# STM32F302x register map
File version: 1.1
Registers are 32-bit, read-write, reset 0x0 unless marked. A register's access mark holds for its fields unless they carry their own. Offsets are from the block's base; [hi:lo] are bit positions; {n}, {i} and the like mark numbered series.

## EXTI — External interrupt/event controller
Base 0x40010400
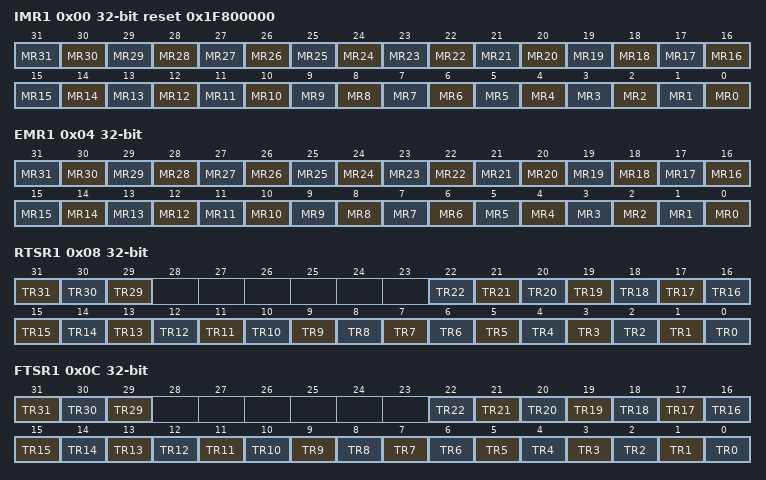
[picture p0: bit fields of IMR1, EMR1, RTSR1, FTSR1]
0x00 IMR1 reset 0x1F800000 — Interrupt mask register
  [n] MR{n} (n=0..31) — Interrupt Mask on line {n}
0x04 EMR1 — Event mask register
  [n] MR{n} (n=0..31) — Event Mask on line {n}
0x08 RTSR1 — Rising Trigger selection register
  [31] TR31 — Rising trigger event configuration of line 31
  [30] TR30 — Rising trigger event configuration of line 30
  [29] TR29 — Rising trigger event configuration of line 29
  [n] TR{n} (n=0..22) — Rising trigger event configuration of line {n}
0x0C FTSR1 — Falling Trigger selection register
  [31] TR31 — Falling trigger event configuration of line 31
  [30] TR30 — Falling trigger event configuration of line 30.
  [29] TR29 — Falling trigger event configuration of line 29
  [n] TR{n} (n=0..22) — Falling trigger event configuration of line {n}
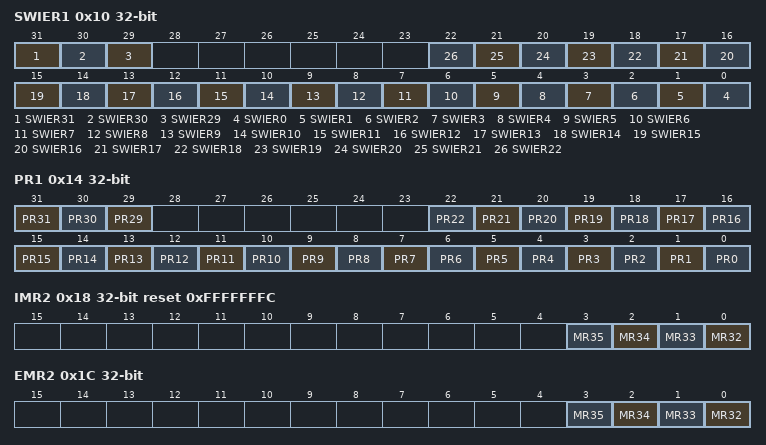
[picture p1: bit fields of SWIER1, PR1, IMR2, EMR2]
0x10 SWIER1 — Software interrupt event register
  [31] SWIER31 — Software Interrupt on line 319
  [30] SWIER30 — Software Interrupt on line 309
  [29] SWIER29 — Software Interrupt on line 29
  [n] SWIER{n} (n=0..22) — Software Interrupt on line {n}
0x14 PR1 — Pending register
  [31] PR31 — Pending bit 31
  [30] PR30 — Pending bit 30
  [29] PR29 — Pending bit 29
  [n] PR{n} (n=0..22) — Pending bit {n}
0x18 IMR2 reset 0xFFFFFFFC — Interrupt mask register
  [n-32] MR{n} (n=32..35) — Interrupt Mask on external/internal line {n}
0x1C EMR2 — Event mask register
  [n-32] MR{n} (n=32..35) — Event mask on external/internal line {n}
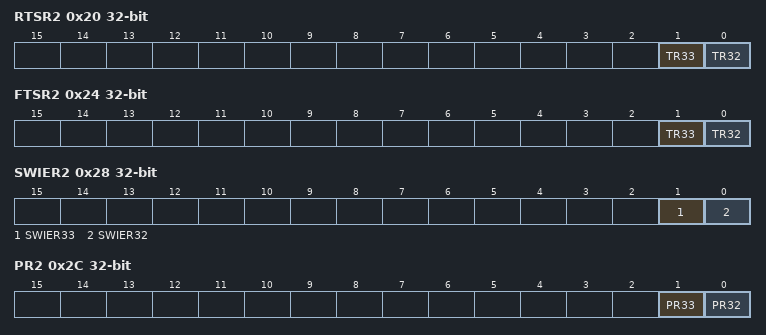
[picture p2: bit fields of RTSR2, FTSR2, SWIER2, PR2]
0x20 RTSR2 — Rising Trigger selection register
  [1] TR33 — Rising trigger event configuration bit of line 33
  [0] TR32 — Rising trigger event configuration bit of line 32
0x24 FTSR2 — Falling Trigger selection register
  [1] TR33 — Falling trigger event configuration bit of line 33
  [0] TR32 — Falling trigger event configuration bit of line 32
0x28 SWIER2 — Software interrupt event register
  [1] SWIER33 — Software interrupt on line 33
  [0] SWIER32 — Software interrupt on line 32
0x2C PR2 — Pending register
  [1] PR33 — Pending bit on line 33
  [0] PR32 — Pending bit on line 32

## COMP — Comparator
Base 0x4001001C
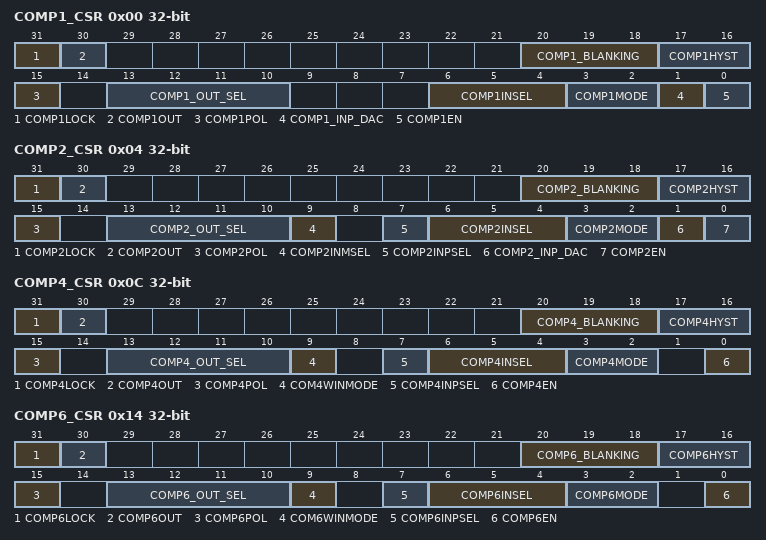
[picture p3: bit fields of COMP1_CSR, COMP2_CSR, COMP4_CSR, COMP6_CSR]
0x00 COMP1_CSR access per field — control and status register
  [31] COMP1LOCK rw — Comparator 1 lock
  [30] COMP1OUT ro — Comparator 1 output
  [20:18] COMP1_BLANKING rw — Comparator 1 blanking source
  [17:16] COMP1HYST rw — Comparator 1 hysteresis
  [15] COMP1POL rw — Comparator 1 output polarity
  [13:10] COMP1_OUT_SEL rw — Comparator 1 output selection
  [6:4] COMP1INSEL rw — Comparator 1 inverting input selection
  [3:2] COMP1MODE rw — Comparator 1 mode
  [1] COMP1_INP_DAC rw — Comparator1 non inverting input connection to DAC output
  [0] COMP1EN rw — Comparator 1 enable
0x04 COMP2_CSR access per field — control and status register
  [31] COMP2LOCK rw — Comparator 2 lock
  [30] COMP2OUT ro — Comparator 2 output
  [20:18] COMP2_BLANKING rw — Comparator 2 blanking source
  [17:16] COMP2HYST rw — Comparator 2 hysteresis
  [15] COMP2POL rw — Comparator 2 output polarity
  [13:10] COMP2_OUT_SEL rw — Comparator 2 output selection
  [9] COMP2INMSEL rw — Comparator 1inverting input selection
  [7] COMP2INPSEL rw — Comparator 2 non inverted input selection
  [6:4] COMP2INSEL rw — Comparator 2 inverting input selection
  [3:2] COMP2MODE rw — Comparator 2 mode
  [1] COMP2_INP_DAC rw — Comparator2 non inverting input connection to DAC output
  [0] COMP2EN rw — Comparator 2 enable
0x0C COMP4_CSR access per field — control and status register
  [31] COMP4LOCK rw — Comparator 4 lock
  [30] COMP4OUT ro — Comparator 4 output
  [20:18] COMP4_BLANKING rw — Comparator 4 blanking source
  [17:16] COMP4HYST rw — Comparator 4 hysteresis
  [15] COMP4POL rw — Comparator 4 output polarity
  [13:10] COMP4_OUT_SEL rw — Comparator 4 output selection
  [9] COM4WINMODE rw — Comparator 4 window mode
  [7] COMP4INPSEL rw — Comparator 4 non inverted input selection
  [6:4] COMP4INSEL rw — Comparator 4 inverting input selection
  [3:2] COMP4MODE rw — Comparator 4 mode
  [0] COMP4EN rw — Comparator 4 enable
0x14 COMP6_CSR access per field — control and status register
  [31] COMP6LOCK rw — Comparator 6 lock
  [30] COMP6OUT ro — Comparator 6 output
  [20:18] COMP6_BLANKING rw — Comparator 6 blanking source
  [17:16] COMP6HYST rw — Comparator 6 hysteresis
  [15] COMP6POL rw — Comparator 6 output polarity
  [13:10] COMP6_OUT_SEL rw — Comparator 6 output selection
  [9] COM6WINMODE rw — Comparator 6 window mode
  [7] COMP6INPSEL rw — Comparator 6 non inverted input selection
  [6:4] COMP6INSEL rw — Comparator 6 inverting input selection
  [3:2] COMP6MODE rw — Comparator 6 mode
  [0] COMP6EN rw — Comparator 6 enable
